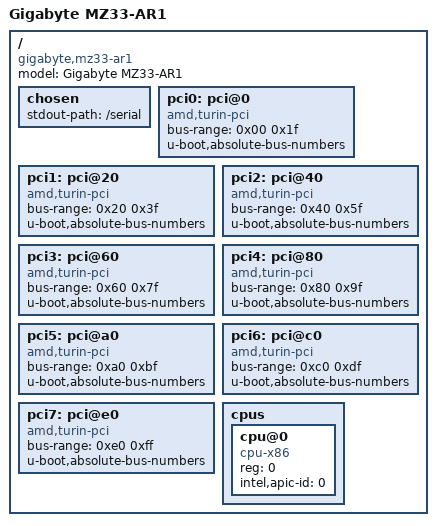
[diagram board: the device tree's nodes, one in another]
// SPDX-License-Identifier: GPL-2.0+
/*
 * Copyright 2026 Simon Glass <sjg@chromium.org>
 *
 * Gigabyte MZ33-AR1 (AMD EPYC Turin) with U-Boot as the PSP's BIOS image
 */

/dts-v1/;

/include/ "skeleton.dtsi"
/include/ "serial.dtsi"
/include/ "reset.dtsi"
#include "tsc_timer.dtsi"

/ {
	model = "Gigabyte MZ33-AR1";
	compatible = "gigabyte,mz33-ar1";

	chosen {
		stdout-path = "/serial";
	};

	/*
	 * One root bus per root complex. Its bus-range gives its own bus
	 * number and those of the buses behind its bridges, which the fabric's
	 * config maps fix at 0x20 apart and which U-Boot uses as they are
	 * (u-boot,absolute-bus-numbers); the ranges are the I/O and MMIO
	 * windows the fabric routes to it, which the host driver
	 * programs. The MMIO hole is the space between the top of low memory
	 * and the compatibility area at 0xfec00000, less the ECAM at
	 * 0xb0000000-0xbfffffff; bus 0 gets the top of it, the rest an equal
	 * share, as openSIL's resource manager does
	 */
	pci0: pci@0 {
		compatible = "amd,turin-pci";
		bus-range = <0x00 0x1f>;
		u-boot,absolute-bus-numbers;
		#address-cells = <3>;
		#size-cells = <2>;
		device_type = "pci";
		ranges = <0x01000000 0 0x1000 0x1000 0 0x1000>,
			 <0x02000000 0 0xf1000000 0xf1000000 0 0x0dc00000>;
	};

	pci1: pci@20 {
		compatible = "amd,turin-pci";
		bus-range = <0x20 0x3f>;
		u-boot,absolute-bus-numbers;
		#address-cells = <3>;
		#size-cells = <2>;
		device_type = "pci";
		ranges = <0x01000000 0 0x2000 0x2000 0 0x1000>,
			 <0x02000000 0 0xce000000 0xce000000 0 0x07000000>;
	};

	pci2: pci@40 {
		compatible = "amd,turin-pci";
		bus-range = <0x40 0x5f>;
		u-boot,absolute-bus-numbers;
		#address-cells = <3>;
		#size-cells = <2>;
		device_type = "pci";
		ranges = <0x01000000 0 0x3000 0x3000 0 0x1000>,
			 <0x02000000 0 0xc7000000 0xc7000000 0 0x07000000>;
	};

	pci3: pci@60 {
		compatible = "amd,turin-pci";
		bus-range = <0x60 0x7f>;
		u-boot,absolute-bus-numbers;
		#address-cells = <3>;
		#size-cells = <2>;
		device_type = "pci";
		ranges = <0x01000000 0 0x4000 0x4000 0 0x1000>,
			 <0x02000000 0 0xc0000000 0xc0000000 0 0x07000000>;
	};

	pci4: pci@80 {
		compatible = "amd,turin-pci";
		bus-range = <0x80 0x9f>;
		u-boot,absolute-bus-numbers;
		#address-cells = <3>;
		#size-cells = <2>;
		device_type = "pci";
		ranges = <0x01000000 0 0x5000 0x5000 0 0x1000>,
			 <0x02000000 0 0xd5000000 0xd5000000 0 0x07000000>;
	};

	pci5: pci@a0 {
		compatible = "amd,turin-pci";
		bus-range = <0xa0 0xbf>;
		u-boot,absolute-bus-numbers;
		#address-cells = <3>;
		#size-cells = <2>;
		device_type = "pci";
		ranges = <0x01000000 0 0x6000 0x6000 0 0x1000>,
			 <0x02000000 0 0xdc000000 0xdc000000 0 0x07000000>;
	};

	pci6: pci@c0 {
		compatible = "amd,turin-pci";
		bus-range = <0xc0 0xdf>;
		u-boot,absolute-bus-numbers;
		#address-cells = <3>;
		#size-cells = <2>;
		device_type = "pci";
		ranges = <0x01000000 0 0x7000 0x7000 0 0x1000>,
			 <0x02000000 0 0xe3000000 0xe3000000 0 0x07000000>;
	};

	pci7: pci@e0 {
		compatible = "amd,turin-pci";
		bus-range = <0xe0 0xff>;
		u-boot,absolute-bus-numbers;
		#address-cells = <3>;
		#size-cells = <2>;
		device_type = "pci";
		ranges = <0x01000000 0 0x8000 0x8000 0 0x1000>,
			 <0x02000000 0 0xea000000 0xea000000 0 0x07000000>;
	};

	cpus {
		#address-cells = <1>;
		#size-cells = <0>;
		bootph-all;

		cpu@0 {
			device_type = "cpu";
			compatible = "cpu-x86";
			bootph-all;
			reg = <0>;
			intel,apic-id = <0>;
		};
	};
};
